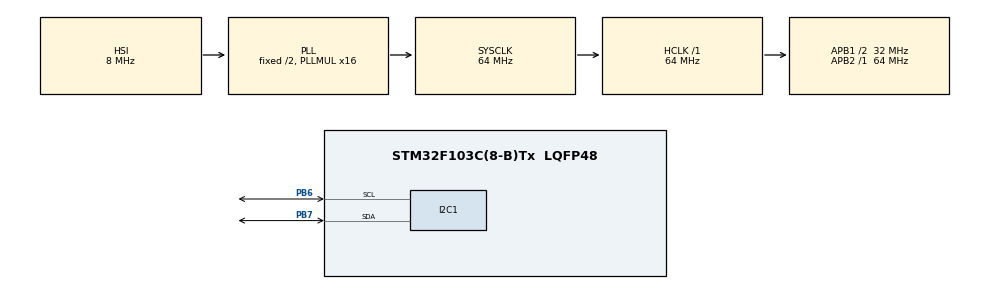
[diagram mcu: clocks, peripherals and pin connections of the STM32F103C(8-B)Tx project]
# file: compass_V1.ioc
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I2C1.I2C_Mode=I2C_Fast
Mcu.Family=STM32F1
Mcu.Name=STM32F103C(8-B)Tx
Mcu.Package=LQFP48
NVIC.I2C1_ER_IRQn=true\:0\:0\:false\:false\:true\:true\:true\:true
NVIC.I2C1_EV_IRQn=true\:0\:0\:false\:false\:true\:true\:true\:true
NVIC.PriorityGroup=NVIC_PRIORITYGROUP_4
NVIC.TIM1_BRK_IRQn=true\:0\:0\:false\:false\:true\:true\:true\:true
NVIC.TIM1_CC_IRQn=true\:0\:0\:false\:false\:true\:true\:true\:true
NVIC.TIM1_TRG_COM_IRQn=true\:0\:0\:false\:false\:true\:true\:true\:true
NVIC.TIM1_UP_IRQn=true\:0\:0\:false\:false\:true\:true\:true\:true
PA13.Mode=Serial_Wire
PA13.Signal=SYS_JTMS-SWDIO
PA14.Mode=Serial_Wire
PA14.Signal=SYS_JTCK-SWCLK
PB6.Mode=I2C
PB6.Signal=I2C1_SCL
PB7.Mode=I2C
PB7.Signal=I2C1_SDA
ProjectManager.HeapSize=0x200
ProjectManager.StackSize=0x400
ProjectManager.TargetToolchain=EWARM V8
RCC.AHBFreq_Value=64000000
RCC.APB1CLKDivider=RCC_HCLK_DIV2
RCC.APB1Freq_Value=32000000
RCC.APB1TimFreq_Value=64000000
RCC.APB2Freq_Value=64000000
RCC.APB2TimFreq_Value=64000000
RCC.HCLKFreq_Value=64000000
RCC.PLLMUL=RCC_PLL_MUL16
RCC.SYSCLKFreq_VALUE=64000000
RCC.SYSCLKSource=RCC_SYSCLKSOURCE_PLLCLK
RCC.USBFreq_Value=64000000
TIM1.AutoReloadPreload=TIM_AUTORELOAD_PRELOAD_ENABLE
TIM1.Period=999
TIM1.Prescaler=63
VP_TIM1_VS_ClockSourceINT.Mode=Internal
board=custom

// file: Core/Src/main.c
/* USER CODE BEGIN Header */
/**
  ******************************************************************************
  * @file           : main.c
  * @brief          : Main program body
  ******************************************************************************
  * @attention
  *
  * Copyright (c) 2024 STMicroelectronics.
  * All rights reserved.
  *
  * This software is licensed under terms that can be found in the LICENSE file
  * in the root directory of this software component.
  * If no LICENSE file comes with this software, it is provided AS-IS.
  *
  ******************************************************************************
  */
/* USER CODE END Header */
#include "main.h"

/* USER CODE BEGIN Includes */
#include "imu.h"
/* USER CODE END Includes */

I2C_HandleTypeDef hi2c1;

TIM_HandleTypeDef htim1;

void SystemClock_Config(void);
static void MX_GPIO_Init(void);
static void MX_I2C1_Init(void);
static void MX_TIM1_Init(void);

/* USER CODE BEGIN 0 */
void HAL_TIM_PeriodElapsedCallback(TIM_HandleTypeDef *htim)
{
    if (htim->Instance == TIM1)
    {
      imu_return();
    }
    else
    {
    }
}
/* USER CODE END 0 */

int main(void)
{

  /* MCU Configuration--------------------------------------------------------*/

  /* Reset of all peripherals, Initializes the Flash interface and the Systick. */
  HAL_Init();

  /* Configure the system clock */
  SystemClock_Config();

  /* Initialize all configured peripherals */
  MX_GPIO_Init();
  MX_I2C1_Init();
  MX_TIM1_Init();
  /* USER CODE BEGIN 2 */
  HAL_TIM_Base_Start_IT(&htim1);
  imu_init();
  imu_calib();
  imu_reset();
  /* USER CODE END 2 */

  /* Infinite loop */
  while (1)
  {

  }
}

void SystemClock_Config(void)
{
  RCC_OscInitTypeDef RCC_OscInitStruct = {0};
  RCC_ClkInitTypeDef RCC_ClkInitStruct = {0};

  /** Initializes the RCC Oscillators according to the specified parameters
  * in the RCC_OscInitTypeDef structure.
  */
  RCC_OscInitStruct.OscillatorType = RCC_OSCILLATORTYPE_HSI;
  RCC_OscInitStruct.HSIState = RCC_HSI_ON;
  RCC_OscInitStruct.HSICalibrationValue = RCC_HSICALIBRATION_DEFAULT;
  RCC_OscInitStruct.PLL.PLLState = RCC_PLL_ON;
  RCC_OscInitStruct.PLL.PLLSource = RCC_PLLSOURCE_HSI_DIV2;
  RCC_OscInitStruct.PLL.PLLMUL = RCC_PLL_MUL16;
  if (HAL_RCC_OscConfig(&RCC_OscInitStruct) != HAL_OK)
  {
    Error_Handler();
  }

  /** Initializes the CPU, AHB and APB buses clocks
  */
  RCC_ClkInitStruct.ClockType = RCC_CLOCKTYPE_HCLK|RCC_CLOCKTYPE_SYSCLK
                              |RCC_CLOCKTYPE_PCLK1|RCC_CLOCKTYPE_PCLK2;
  RCC_ClkInitStruct.SYSCLKSource = RCC_SYSCLKSOURCE_PLLCLK;
  RCC_ClkInitStruct.AHBCLKDivider = RCC_SYSCLK_DIV1;
  RCC_ClkInitStruct.APB1CLKDivider = RCC_HCLK_DIV2;
  RCC_ClkInitStruct.APB2CLKDivider = RCC_HCLK_DIV1;

  if (HAL_RCC_ClockConfig(&RCC_ClkInitStruct, FLASH_LATENCY_2) != HAL_OK)
  {
    Error_Handler();
  }
}

static void MX_I2C1_Init(void)
{

  hi2c1.Instance = I2C1;
  hi2c1.Init.ClockSpeed = 400000;
  hi2c1.Init.DutyCycle = I2C_DUTYCYCLE_2;
  hi2c1.Init.OwnAddress1 = 0;
  hi2c1.Init.AddressingMode = I2C_ADDRESSINGMODE_7BIT;
  hi2c1.Init.DualAddressMode = I2C_DUALADDRESS_DISABLE;
  hi2c1.Init.OwnAddress2 = 0;
  hi2c1.Init.GeneralCallMode = I2C_GENERALCALL_DISABLE;
  hi2c1.Init.NoStretchMode = I2C_NOSTRETCH_DISABLE;
  if (HAL_I2C_Init(&hi2c1) != HAL_OK)
  {
    Error_Handler();
  }

}

static void MX_TIM1_Init(void)
{

  TIM_ClockConfigTypeDef sClockSourceConfig = {0};
  TIM_MasterConfigTypeDef sMasterConfig = {0};

  htim1.Instance = TIM1;
  htim1.Init.Prescaler = 639;
  htim1.Init.CounterMode = TIM_COUNTERMODE_UP;
  htim1.Init.Period = 999;
  htim1.Init.ClockDivision = TIM_CLOCKDIVISION_DIV1;
  htim1.Init.RepetitionCounter = 0;
  htim1.Init.AutoReloadPreload = TIM_AUTORELOAD_PRELOAD_ENABLE;
  if (HAL_TIM_Base_Init(&htim1) != HAL_OK)
  {
    Error_Handler();
  }
  sClockSourceConfig.ClockSource = TIM_CLOCKSOURCE_INTERNAL;
  if (HAL_TIM_ConfigClockSource(&htim1, &sClockSourceConfig) != HAL_OK)
  {
    Error_Handler();
  }
  sMasterConfig.MasterOutputTrigger = TIM_TRGO_RESET;
  sMasterConfig.MasterSlaveMode = TIM_MASTERSLAVEMODE_DISABLE;
  if (HAL_TIMEx_MasterConfigSynchronization(&htim1, &sMasterConfig) != HAL_OK)
  {
    Error_Handler();
  }

}

static void MX_GPIO_Init(void)
{

  /* GPIO Ports Clock Enable */
  __HAL_RCC_GPIOA_CLK_ENABLE();
  __HAL_RCC_GPIOB_CLK_ENABLE();

}

void Error_Handler(void)
{
  __disable_irq();
  while (1)
  {
  }
}
